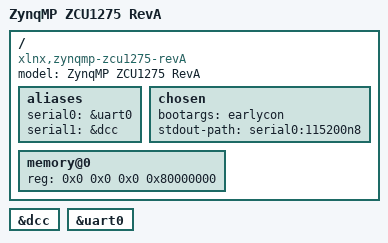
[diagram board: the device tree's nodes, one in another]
// SPDX-License-Identifier: GPL-2.0+
/*
 * dts file for Xilinx ZynqMP ZCU1275
 *
 * (C) Copyright 2017 - 2019, Xilinx, Inc.
 *
 * Michal Simek <michal.simek@xilinx.com>
 * Siva Durga Prasad Paladugu <sivadur@xilinx.com>
 */

/dts-v1/;

#include "zynqmp.dtsi"
#include "zynqmp-clk-ccf.dtsi"

/ {
	model = "ZynqMP ZCU1275 RevA";
	compatible = "xlnx,zynqmp-zcu1275-revA", "xlnx,zynqmp-zcu1275", "xlnx,zynqmp";

	aliases {
		serial0 = &uart0;
		serial1 = &dcc;
	};

	chosen {
		bootargs = "earlycon";
		stdout-path = "serial0:115200n8";
	};

	memory@0 {
		device_type = "memory";
		reg = <0x0 0x0 0x0 0x80000000>;
	};
};

&dcc {
	status = "okay";
};

&uart0 {
	status = "okay";
};
